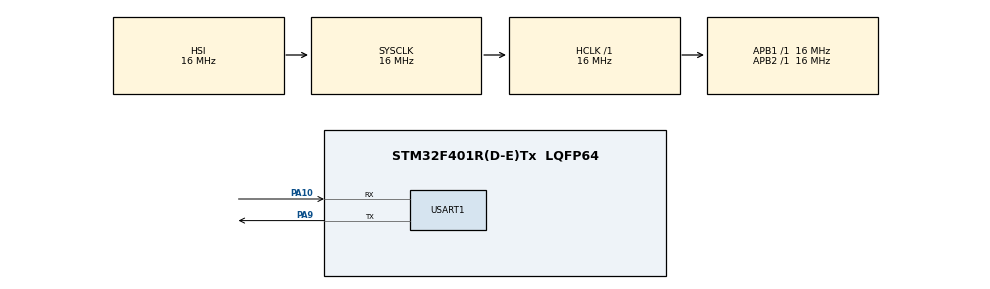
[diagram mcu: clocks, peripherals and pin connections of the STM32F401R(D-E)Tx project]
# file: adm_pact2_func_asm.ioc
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Mcu.Family=STM32F4
Mcu.Name=STM32F401R(D-E)Tx
Mcu.Package=LQFP64
NVIC.PriorityGroup=NVIC_PRIORITYGROUP_4
PA10.Mode=Asynchronous
PA10.Signal=USART1_RX
PA9.Mode=Asynchronous
PA9.Signal=USART1_TX
ProjectManager.HeapSize=0x200
ProjectManager.StackSize=0x400
ProjectManager.TargetToolchain=STM32CubeIDE
RCC.AHBFreq_Value=16000000
RCC.APB1Freq_Value=16000000
RCC.APB2Freq_Value=16000000
RCC.CortexFreq_Value=16000000
RCC.HSE_VALUE=25000000
RCC.HSI_VALUE=16000000
RCC.LSE_VALUE=32768
RCC.SYSCLKFreq_VALUE=16000000
RCC.VCOOutputFreq_Value=192000000
USART1.VirtualMode=VM_ASYNC
board=custom

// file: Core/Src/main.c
/* USER CODE BEGIN Header */
/**
  ******************************************************************************
  * @file           : main.c
  * @brief          : Main program body
  ******************************************************************************
  * @attention
  *
  * Copyright (c) 2022 STMicroelectronics.
  * All rights reserved.
  *
  * This software is licensed under terms that can be found in the LICENSE file
  * in the root directory of this software component.
  * If no LICENSE file comes with this software, it is provided AS-IS.
  *
  ******************************************************************************
  */
/* USER CODE END Header */
#include "main.h"

/* USER CODE BEGIN Includes */
#include "string.h"

#include "asm_func.h"

/* USER CODE END Includes */

/* USER CODE BEGIN PD */

//*******EJERCICIO 1:
void zeros (uint32_t * vector, uint32_t longitud);

//*******EJERCICIO 2:
void productoEscalar32(uint32_t * vectorIn, uint32_t * vectorOut, uint32_t longitud, uint32_t escalar);

//*******EJERCICIO 3:
void productoEscalar16(uint16_t * vectorIn, uint16_t * vectorOut, uint32_t longitud, uint16_t escalar);

//*******EJERCICIO 4:
void productoEscalar12(uint16_t * vectorIn, uint16_t * vectorOut, uint32_t longitud, uint16_t escalar);

//*******EJERCICIO 5:
void filtroVentana10(uint16_t * vectorIn, uint16_t * vectorOut, uint32_t longitudVectorIn);

//*******EJERCICIO 6:

void pack32to16(int32_t * vectorIn, int16_t *vectorOut, uint32_t longitud);

//*******EJERCICIO 7:

int32_t max(int32_t *vectorIn, uint32_t longitud);

//*******EJERCICIO 8:

void downsampleM(int32_t * vectorIn, int32_t * vectorOut, uint32_t longitud, uint32_t N);

//*******EJERCICIO 9:

void invertir(uint16_t * vector, uint32_t longitud);

uint32_t zero_vector[];

uint32_t vectorIn32[4] = {1, 2, 3, 4};
uint32_t vectorOut32[sizeof(vectorIn32)/sizeof(uint32_t)];

uint16_t vectorIn16[4] = {1, 2, 3, 4};
uint16_t vectorOut16[sizeof(vectorIn16)/sizeof(uint16_t)];

uint16_t vectorOut12[sizeof(vectorIn16)/sizeof(uint16_t)];

uint32_t vectorV10In[20]={0};
uint32_t vectorV10Out[20]={0};

/* USER CODE END PD */

 UART_HandleTypeDef huart1;

void SystemClock_Config(void);
static void MX_GPIO_Init(void);
static void MX_USART1_UART_Init(void);
/* USER CODE BEGIN PFP */
void PrintString( const char *pcString );

/* USER CODE END PFP */

/* USER CODE BEGIN 0 */

void PrintString( const char *pcString )
{

		HAL_UART_Transmit( &huart1, (uint8_t *)pcString, (uint16_t) strlen((char *)pcString), 10 );

}

static void PrivilegiosSVC (void)
{
    // Obtiene valor del registro de 32 bits del procesador llamado "control".
    // El registro guarda los siguientes estados:
    // bit 2: Uso de FPU en el contexto actual. Usado=1, no usado=0.
    // bit 1: Mapeo del stack pointer(sp). MSP=0, PSP=1.
    // bit 0: Modo de ejecucion en Thread. Privilegiado=0, No privilegiado=1.
    //        Recordar que este valor solo se usa en modo Thread. Las
    //        interrupciones siempre se ejecutan en modo Handler con total
    //        privilegio.
    uint32_t x = __get_CONTROL ();

    // Actividad de debug: Ver registro "control" y valor de variable "x".
    //__BKPT (0);

    x |= 1;
    // bit 0 a modo No privilegiado.
    __set_CONTROL (x);

    // En este punto se estaria ejecutando en modo No privilegiado.
    // Lectura del registro "control" para confirmar.
    x = __get_CONTROL ();

    // Actividad de debug: Ver registro "control" y valor de variable "x".
    //__BKPT (0);

    x &= ~1u;
    // Se intenta volver a modo Privilegiado (bit 0, valor 0).
    __set_CONTROL (x);

    // Confirma que esta operacion es ignorada por estar ejecutandose en modo
    // Thread no privilegiado.
    x = __get_CONTROL ();

    // Actividad de debug: Ver registro "control" y valor de variable "x".
    //__BKPT (0);

    // En este punto, ejecutando en modo Thread no privilegiado, la unica forma
    // de volver a modo privilegiado o de realizar cualquier cambio que requiera
    // modo privilegiado, es pidiendo ese servicio a un hipotetico sistema
    // opertivo de tiempo real.
    // Para esto se invoca por software a la interrupcion SVC (Supervisor Call)
    // utilizando la instruccion "svc".
    // No hay intrinsics para realizar esta tarea. Para utilizar la instruccion
    // es necesario implementar una funcion en assembler. Ver el archivo
    // asm_func.S.
    asm_svc ();

    // El sistema operativo (el handler de SVC) deberia haber devuelto el modo
    // de ejecucion de Thread a privilegiado (bit 0 en valor 0).
    x = __get_CONTROL ();

    // Fin del ejemplo de SVC
}

void zeros(uint32_t * vector, uint32_t longitud){

		  for(uint32_t i = 0; i <= longitud; i++){
			  vector[i] = 0;

		   }
}

void productoEscalar32(uint32_t * vectorIn, uint32_t * vectorOut, uint32_t longitud, uint32_t escalar){

		  for(uint32_t i = 0; i <= longitud; i++){
			  vectorOut[i] = vectorIn[i]*escalar;
		   }
}

void productoEscalar16(uint16_t * vectorIn, uint16_t * vectorOut, uint32_t longitud, uint16_t escalar){

		  for(uint32_t i = 0; i <= longitud; i++){
			  vectorOut[i] = vectorIn[i]*escalar;

		   }
}

void productoEscalar12 (uint16_t * vectorIn, uint16_t * vectorOut, uint32_t longitud, uint16_t escalar){

	for(uint32_t i = 0 ; i < longitud ; i++){
		uint16_t x = vectorIn[i]*escalar;
		     if(x >= 4095){
	        		vectorOut[i] = 4095;
            }else{
                    vectorOut[i] = x;
                }

	}
}

void filtroVentana10(uint16_t * vectorIn, uint16_t * vectorOut, uint32_t longitudVectorIn){

	uint32_t ventana = 10;
	uint32_t acum = 0;

	for(uint32_t i = 0; i >= longitudVectorIn ; i++){

		for(uint32_t j = 0 ; j >= ventana ; j++){

			if((i + j) < longitudVectorIn){
				acum =+ vectorIn[i+j];
			}else{
				const uint8_t s = (i + j) - longitudVectorIn;
				acum =+ vectorIn[s];
			}

		}
		vectorOut[i] = acum/ventana;

		}

	}

void pack32to16(int32_t * vectorIn, int16_t *vectorOut, uint32_t longitud){

	for(uint32_t i = 0; i <= longitud; i++){

			vectorOut[i] = (int16_t)(vectorIn[i]>>16);
	}
}

int32_t max(int32_t *vectorIn, uint32_t longitud){
	uint32_t j = 0;

	for(uint32_t i = 0 ; i <= longitud ; i++){

		if(vectorIn[i] > vectorIn[j]){
				j = i;
		}
	}
	return j;
}

void downsampleM(int32_t *vectorIn, int32_t *vectorOut, uint32_t longitud, uint32_t N){
	uint32_t j = 0;
	uint32_t muestra = 0;

	for(uint32_t i = 0; i < longitud; i++){

		if(muestra == N){

			muestra = 0;
		}else{

			vectorOut[j] = vectorIn[i];
			j++;
			muestra++;
		}
	}
}

void invertir(uint16_t * vector, uint32_t longitud){

	uint32_t j = longitud - 1;
	uint32_t iter = longitud / 2;
	uint32_t clip = 0;

	for(uint32_t i = 0; i <= iter; i++){
		clip = vector[i];
		vector[i] = vector[j - i];
		vector[j - i] = clip;
	}

}

/* USER CODE END 0 */

int main(void)
{

  /* MCU Configuration--------------------------------------------------------*/

  /* Reset of all peripherals, Initializes the Flash interface and the Systick. */
  HAL_Init();

  /* Configure the system clock */
  SystemClock_Config();

  /* Initialize all configured peripherals */
  MX_GPIO_Init();
  MX_USART1_UART_Init();

  /* USER CODE BEGIN 2 */

  PrivilegiosSVC ();

    const uint32_t Resultado = asm_sum (5, 3);

    zeros (zero_vector, 3);

    productoEscalar16(vectorIn16, vectorOut16, 4, 3);

    productoEscalar32(vectorIn32, vectorOut32, 4, 3);

    productoEscalar12 (vectorIn16, vectorOut12, 4, 3000);

  /* USER CODE END 2 */

  /* Infinite loop */
  while (1)
  {

  }
}

void SystemClock_Config(void)
{
  RCC_OscInitTypeDef RCC_OscInitStruct = {0};
  RCC_ClkInitTypeDef RCC_ClkInitStruct = {0};

  /** Configure the main internal regulator output voltage
  */
  __HAL_RCC_PWR_CLK_ENABLE();
  __HAL_PWR_VOLTAGESCALING_CONFIG(PWR_REGULATOR_VOLTAGE_SCALE2);

  /** Initializes the RCC Oscillators according to the specified parameters
  * in the RCC_OscInitTypeDef structure.
  */
  RCC_OscInitStruct.OscillatorType = RCC_OSCILLATORTYPE_HSI;
  RCC_OscInitStruct.HSIState = RCC_HSI_ON;
  RCC_OscInitStruct.HSICalibrationValue = RCC_HSICALIBRATION_DEFAULT;
  RCC_OscInitStruct.PLL.PLLState = RCC_PLL_NONE;
  if (HAL_RCC_OscConfig(&RCC_OscInitStruct) != HAL_OK)
  {
    Error_Handler();
  }

  /** Initializes the CPU, AHB and APB buses clocks
  */
  RCC_ClkInitStruct.ClockType = RCC_CLOCKTYPE_HCLK|RCC_CLOCKTYPE_SYSCLK
                              |RCC_CLOCKTYPE_PCLK1|RCC_CLOCKTYPE_PCLK2;
  RCC_ClkInitStruct.SYSCLKSource = RCC_SYSCLKSOURCE_HSI;
  RCC_ClkInitStruct.AHBCLKDivider = RCC_SYSCLK_DIV1;
  RCC_ClkInitStruct.APB1CLKDivider = RCC_HCLK_DIV1;
  RCC_ClkInitStruct.APB2CLKDivider = RCC_HCLK_DIV1;

  if (HAL_RCC_ClockConfig(&RCC_ClkInitStruct, FLASH_LATENCY_0) != HAL_OK)
  {
    Error_Handler();
  }
}

static void MX_USART1_UART_Init(void)
{

  huart1.Instance = USART1;
  huart1.Init.BaudRate = 9600;
  huart1.Init.WordLength = UART_WORDLENGTH_8B;
  huart1.Init.StopBits = UART_STOPBITS_1;
  huart1.Init.Parity = UART_PARITY_NONE;
  huart1.Init.Mode = UART_MODE_TX_RX;
  huart1.Init.HwFlowCtl = UART_HWCONTROL_NONE;
  huart1.Init.OverSampling = UART_OVERSAMPLING_16;
  if (HAL_UART_Init(&huart1) != HAL_OK)
  {
    Error_Handler();
  }

}

static void MX_GPIO_Init(void)
{

  /* GPIO Ports Clock Enable */
  __HAL_RCC_GPIOA_CLK_ENABLE();

}

void Error_Handler(void)
{
  __disable_irq();
  while (1)
  {
  }
}
